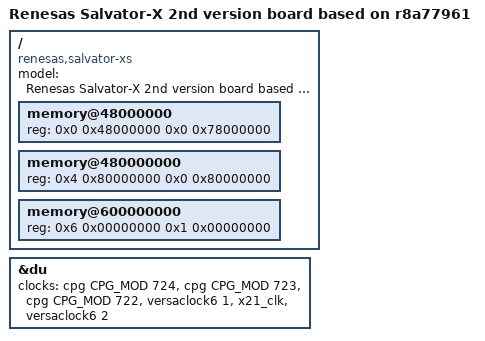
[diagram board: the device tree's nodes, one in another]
// SPDX-License-Identifier: GPL-2.0
/*
 * Device Tree Source for the Salvator-X 2nd version board with R-Car M3-W+
 *
 * Copyright (C) 2018 Renesas Electronics Corp.
 */

/dts-v1/;
#include "r8a77961.dtsi"
#include "salvator-xs.dtsi"

/ {
	model = "Renesas Salvator-X 2nd version board based on r8a77961";
	compatible = "renesas,salvator-xs", "renesas,r8a77961";

	memory@48000000 {
		device_type = "memory";
		/* first 128MB is reserved for secure area. */
		reg = <0x0 0x48000000 0x0 0x78000000>;
	};

	memory@480000000 {
		device_type = "memory";
		reg = <0x4 0x80000000 0x0 0x80000000>;
	};

	memory@600000000 {
		device_type = "memory";
		reg = <0x6 0x00000000 0x1 0x00000000>;
	};
};

&du {
	clocks = <&cpg CPG_MOD 724>,
		 <&cpg CPG_MOD 723>,
		 <&cpg CPG_MOD 722>,
		 <&versaclock6 1>,
		 <&x21_clk>,
		 <&versaclock6 2>;
	clock-names = "du.0", "du.1", "du.2",
		      "dclkin.0", "dclkin.1", "dclkin.2";
};
